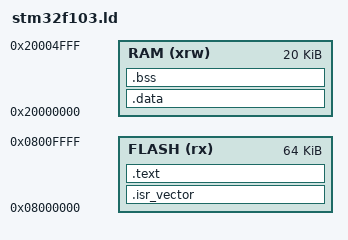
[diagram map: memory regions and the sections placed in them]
/* stm32f103.ld - Linker script for STM32F103C8T6 (64KB Flash, 20KB RAM) */

ENTRY(Reset_Handler)

MEMORY
{
  FLASH (rx) : ORIGIN = 0x08000000, LENGTH = 64K
  RAM (xrw)  : ORIGIN = 0x20000000, LENGTH = 20K
}

_estack = ORIGIN(RAM) + LENGTH(RAM);

SECTIONS
{
  .isr_vector :
  {
    KEEP(*(.isr_vector))
  } > FLASH

  .text :
  {
    *(.text*)
    *(.rodata*)
    KEEP(*(.init))
    KEEP(*(.fini))
  } > FLASH

  .data : AT (ADDR(.text) + SIZEOF(.text))
  {
    _sdata = .;
    *(.data*)
    _edata = .;
  } > RAM

  .bss :
  {
    _sbss = .;
    *(.bss*)
    *(COMMON)
    _ebss = .;
  } > RAM
}
